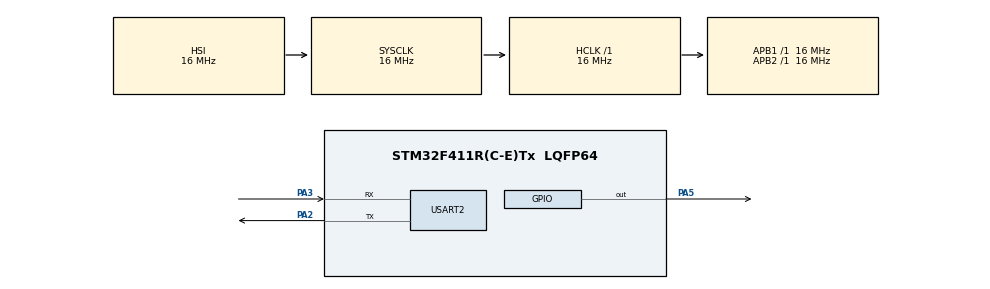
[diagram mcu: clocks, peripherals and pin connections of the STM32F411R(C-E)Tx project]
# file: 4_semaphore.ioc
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FREERTOS.Tasks01=defaultTask,24,128,StartDefaultTask,Default,NULL,Dynamic,NULL,NULL
FREERTOS.configUSE_NEWLIB_REENTRANT=1
Mcu.Family=STM32F4
Mcu.Name=STM32F411R(C-E)Tx
Mcu.Package=LQFP64
NVIC.PriorityGroup=NVIC_PRIORITYGROUP_4
NVIC.TIM1_TRG_COM_TIM11_IRQn=true\:15\:0\:false\:false\:true\:false\:false\:true\:true
NVIC.TimeBase=TIM1_TRG_COM_TIM11_IRQn
NVIC.TimeBaseIP=TIM11
PA2.Mode=Asynchronous
PA2.Signal=USART2_TX
PA3.Mode=Asynchronous
PA3.Signal=USART2_RX
PA5.Signal=GPIO_Output
ProjectManager.HeapSize=0x200
ProjectManager.StackSize=0x400
ProjectManager.TargetToolchain=STM32CubeIDE
RCC.AHBFreq_Value=16000000
RCC.APB1Freq_Value=16000000
RCC.APB2Freq_Value=16000000
RCC.CortexFreq_Value=16000000
RCC.HSE_VALUE=25000000
RCC.HSI_VALUE=16000000
RCC.LSE_VALUE=32768
RCC.SYSCLKFreq_VALUE=16000000
RCC.VCOOutputFreq_Value=192000000
USART2.VirtualMode=VM_ASYNC
VP_FREERTOS_VS_CMSIS_V2.Mode=CMSIS_V2
VP_SYS_VS_tim11.Mode=TIM11
board=custom

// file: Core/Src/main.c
/* USER CODE BEGIN Header */
/**
  ******************************************************************************
  * @file           : main.c
  * @brief          : Main program body
  ******************************************************************************
  * @attention
  *
  * Copyright (c) 2026 STMicroelectronics.
  * All rights reserved.
  *
  * This software is licensed under terms that can be found in the LICENSE file
  * in the root directory of this software component.
  * If no LICENSE file comes with this software, it is provided AS-IS.
  *
  ******************************************************************************
  */
/* USER CODE END Header */
#include "main.h"
#include "cmsis_os.h"

/* USER CODE BEGIN Includes */
#include <stdio.h>
#include <stdlib.h>
#include <string.h>
#include "semphr.h"
#include <math.h>

/* USER CODE END Includes */

UART_HandleTypeDef huart2;

/* Definitions for defaultTask */
osThreadId_t defaultTaskHandle;
const osThreadAttr_t defaultTask_attributes = {
  .name = "defaultTask",
  .stack_size = 128 * 4,
  .priority = (osPriority_t) osPriorityNormal,
};
/* USER CODE BEGIN PV */

/* ----------------------------- VARIABLES ---------------------------- */

// Settings
enum {BUF_SIZE = 5};                  // Size of buffer array
#define NUM_PROD_TASKS 5  			  // Number of producer tasks
#define NUM_CONS_TASKS 2			  // Number of consumer tasks
static const int num_writes = 3;      // Num times each producer writes to buf

// Globals
static int buf[BUF_SIZE];             // Shared buffer
static int head = 0;                  // Writing index to buffer
static int tail = 0;                  // Reading index to buffer
static SemaphoreHandle_t bin_sem;     // Waits for parameter to be read
static SemaphoreHandle_t mutex_uart;  // Makes the UART acces a critical region

static SemaphoreHandle_t count_filled_sem;
static SemaphoreHandle_t count_empty_sem;

static SemaphoreHandle_t mutex_buff;

/* ------------------------------ TASKS ------------------------------ */

osThreadId_t *prodTaskHandles;
osThreadId_t *conTaskHandles;
osThreadAttr_t *prodTask_attributes;
osThreadAttr_t *conTask_attributes;

static char prod_names[NUM_PROD_TASKS][12];
static char cons_names[NUM_CONS_TASKS][12];

/* USER CODE END PV */

void SystemClock_Config(void);
static void MX_GPIO_Init(void);
static void MX_USART2_UART_Init(void);
void StartDefaultTask(void *argument);

/* USER CODE BEGIN PFP */

/* ------------------------ FUNCTION SIGNATURES ----------------------- */

void consumer(void *argument);

/* USER CODE END PFP */

int main(void)
{

  /* MCU Configuration--------------------------------------------------------*/

  /* Reset of all peripherals, Initializes the Flash interface and the Systick. */
  HAL_Init();

  /* Configure the system clock */
  SystemClock_Config();

  /* Initialize all configured peripherals */
  MX_GPIO_Init();
  MX_USART2_UART_Init();
  /* USER CODE BEGIN 2 */

  /* Disable internal buffering for stdin */
  setvbuf(stdin, NULL, _IONBF, 0);

  /* USER CODE END 2 */

  /* Init scheduler */
  osKernelInitialize();

  /* Create the thread(s) */
  /* creation of defaultTask */
  defaultTaskHandle = osThreadNew(StartDefaultTask, NULL, &defaultTask_attributes);

  /* Start scheduler */
  osKernelStart();

  /* We should never get here as control is now taken by the scheduler */

  /* Infinite loop */
  while (1)
  {

  }
}

void SystemClock_Config(void)
{
  RCC_OscInitTypeDef RCC_OscInitStruct = {0};
  RCC_ClkInitTypeDef RCC_ClkInitStruct = {0};

  /** Configure the main internal regulator output voltage
  */
  __HAL_RCC_PWR_CLK_ENABLE();
  __HAL_PWR_VOLTAGESCALING_CONFIG(PWR_REGULATOR_VOLTAGE_SCALE1);

  /** Initializes the RCC Oscillators according to the specified parameters
  * in the RCC_OscInitTypeDef structure.
  */
  RCC_OscInitStruct.OscillatorType = RCC_OSCILLATORTYPE_HSI;
  RCC_OscInitStruct.HSIState = RCC_HSI_ON;
  RCC_OscInitStruct.HSICalibrationValue = RCC_HSICALIBRATION_DEFAULT;
  RCC_OscInitStruct.PLL.PLLState = RCC_PLL_NONE;
  if (HAL_RCC_OscConfig(&RCC_OscInitStruct) != HAL_OK)
  {
    Error_Handler();
  }

  /** Initializes the CPU, AHB and APB buses clocks
  */
  RCC_ClkInitStruct.ClockType = RCC_CLOCKTYPE_HCLK|RCC_CLOCKTYPE_SYSCLK
                              |RCC_CLOCKTYPE_PCLK1|RCC_CLOCKTYPE_PCLK2;
  RCC_ClkInitStruct.SYSCLKSource = RCC_SYSCLKSOURCE_HSI;
  RCC_ClkInitStruct.AHBCLKDivider = RCC_SYSCLK_DIV1;
  RCC_ClkInitStruct.APB1CLKDivider = RCC_HCLK_DIV1;
  RCC_ClkInitStruct.APB2CLKDivider = RCC_HCLK_DIV1;

  if (HAL_RCC_ClockConfig(&RCC_ClkInitStruct, FLASH_LATENCY_0) != HAL_OK)
  {
    Error_Handler();
  }
}

static void MX_USART2_UART_Init(void)
{

  huart2.Instance = USART2;
  huart2.Init.BaudRate = 300;
  huart2.Init.WordLength = UART_WORDLENGTH_8B;
  huart2.Init.StopBits = UART_STOPBITS_1;
  huart2.Init.Parity = UART_PARITY_NONE;
  huart2.Init.Mode = UART_MODE_TX_RX;
  huart2.Init.HwFlowCtl = UART_HWCONTROL_NONE;
  huart2.Init.OverSampling = UART_OVERSAMPLING_16;
  if (HAL_UART_Init(&huart2) != HAL_OK)
  {
    Error_Handler();
  }

}

static void MX_GPIO_Init(void)
{
  GPIO_InitTypeDef GPIO_InitStruct = {0};

  /* GPIO Ports Clock Enable */
  __HAL_RCC_GPIOA_CLK_ENABLE();

  /*Configure GPIO pin Output Level */
  HAL_GPIO_WritePin(GPIOA, GPIO_PIN_5, GPIO_PIN_RESET);

  /*Configure GPIO pin : PA5 */
  GPIO_InitStruct.Pin = GPIO_PIN_5;
  GPIO_InitStruct.Mode = GPIO_MODE_OUTPUT_PP;
  GPIO_InitStruct.Pull = GPIO_NOPULL;
  GPIO_InitStruct.Speed = GPIO_SPEED_FREQ_LOW;
  HAL_GPIO_Init(GPIOA, &GPIO_InitStruct);

}

/* USER CODE BEGIN 4 */

/* ----------------------- FUNCTION DEFINITIONS ----------------------- */

/* printf redirection */
int __io_putchar(int ch) {
	HAL_UART_Transmit(&huart2, (uint8_t *)&ch, 1, HAL_MAX_DELAY);
	return ch;
}

/* scanf redirection */
int __io_getchar(void) {
	uint8_t ch = 0;

	/* Clear the Overrun flag before reading the first character */
    /* Only clear overrun flag if overrun actually occurred */
    if (__HAL_UART_GET_FLAG(&huart2, UART_FLAG_ORE)) {
        __HAL_UART_CLEAR_OREFLAG(&huart2);
    }

	HAL_UART_Receive(&huart2, (uint8_t *)&ch, 1, HAL_MAX_DELAY);

	if (ch == '\r') ch = '\n';  // Convert CR to LF so gets() terminates

	HAL_UART_Transmit(&huart2, (uint8_t *)&ch, 1, HAL_MAX_DELAY);
	return ch;
}

/* ------------------- FUNCTION DEFINITIONS (TASKS) ------------------- */

// Producer: write a given number of times to shared buffer
void producer(void *argument) {

  // Copy the parameters into a local variable
  int num = *(int *)argument;

  // Release the binary semaphore
  xSemaphoreGive(bin_sem);

  // Fill shared buffer with task number
  for (int i = 0; i < num_writes; i++) {

	xSemaphoreTake(count_empty_sem, portMAX_DELAY);

	xSemaphoreTake(mutex_buff, portMAX_DELAY);
    buf[head] = num;
    head = (head + 1) % BUF_SIZE;
    xSemaphoreGive(mutex_buff);

    xSemaphoreGive(count_filled_sem);

  }

  // Delete self task
  vTaskDelete(NULL);
}

void consumer(void *argument)
{
	int val;

	// Read from buffer
	for(;;) {

		xSemaphoreTake(count_filled_sem, portMAX_DELAY);

		xSemaphoreTake(mutex_buff, portMAX_DELAY);
		val = buf[tail];
		tail = (tail + 1) % BUF_SIZE;
        xSemaphoreTake(mutex_uart, portMAX_DELAY);
        printf("%d\r\n", val);
        xSemaphoreGive(mutex_uart);
        xSemaphoreGive(mutex_buff);

        xSemaphoreGive(count_empty_sem);

	}
}

/* USER CODE END 4 */

void StartDefaultTask(void *argument)
{
  /* USER CODE BEGIN 5 */
//  /* We will get rid of this task */
//  vTaskDelete(NULL);
	// Create mutexes and semaphores before starting tasks
  bin_sem = xSemaphoreCreateBinary();
  mutex_uart = xSemaphoreCreateMutex();
  mutex_buff = xSemaphoreCreateMutex();

  /* For filled: Max count => BUF_SIZE, Initial count => 0 */
  count_filled_sem = xSemaphoreCreateCounting(BUF_SIZE, 0);

  /* For empty: Max count => BUF_SIZE, Initial count => BUF_SIZE */
  count_empty_sem = xSemaphoreCreateCounting(BUF_SIZE, BUF_SIZE);

  prodTaskHandles = pvPortMalloc(NUM_PROD_TASKS * sizeof(osThreadId_t));
  conTaskHandles = pvPortMalloc(NUM_CONS_TASKS * sizeof(osThreadId_t));
  prodTask_attributes = pvPortMalloc(NUM_PROD_TASKS * sizeof(osThreadAttr_t));
  conTask_attributes = pvPortMalloc(NUM_CONS_TASKS * sizeof(osThreadAttr_t));

  // Start producer tasks (wait for each to read argument)
  for (int i = 0; i < NUM_PROD_TASKS; i++) {
     sprintf(prod_names[i], "Producer %i", i);

     prodTask_attributes[i] = (osThreadAttr_t){
    	 .name = prod_names[i],
		 .stack_size = 512 * 4,
		 .priority = (osPriority_t) osPriorityNormal,
     };

     prodTaskHandles[i] = osThreadNew(producer, (void *)&i, &(prodTask_attributes[i]));

     xSemaphoreTake(bin_sem, portMAX_DELAY);
   }

  // Start consumer tasks
  for (int i = 0; i < NUM_CONS_TASKS; i++) {
	  sprintf(cons_names[i], "Consumer %i", i);

	  conTask_attributes[i] = (osThreadAttr_t){
		.name = cons_names[i],
		.stack_size = 512 * 4,
		.priority = (osPriority_t) osPriorityNormal,
	  };

	  conTaskHandles[i] = osThreadNew(consumer, NULL, &(conTask_attributes[i]));

  }

    printf("All tasks created\r\n");

    vTaskDelete(NULL);
  /* USER CODE END 5 */
}

void HAL_TIM_PeriodElapsedCallback(TIM_HandleTypeDef *htim)
{
  if (htim->Instance == TIM11)
  {
    HAL_IncTick();
  }
}

void Error_Handler(void)
{
  __disable_irq();
  while (1)
  {
  }
}
